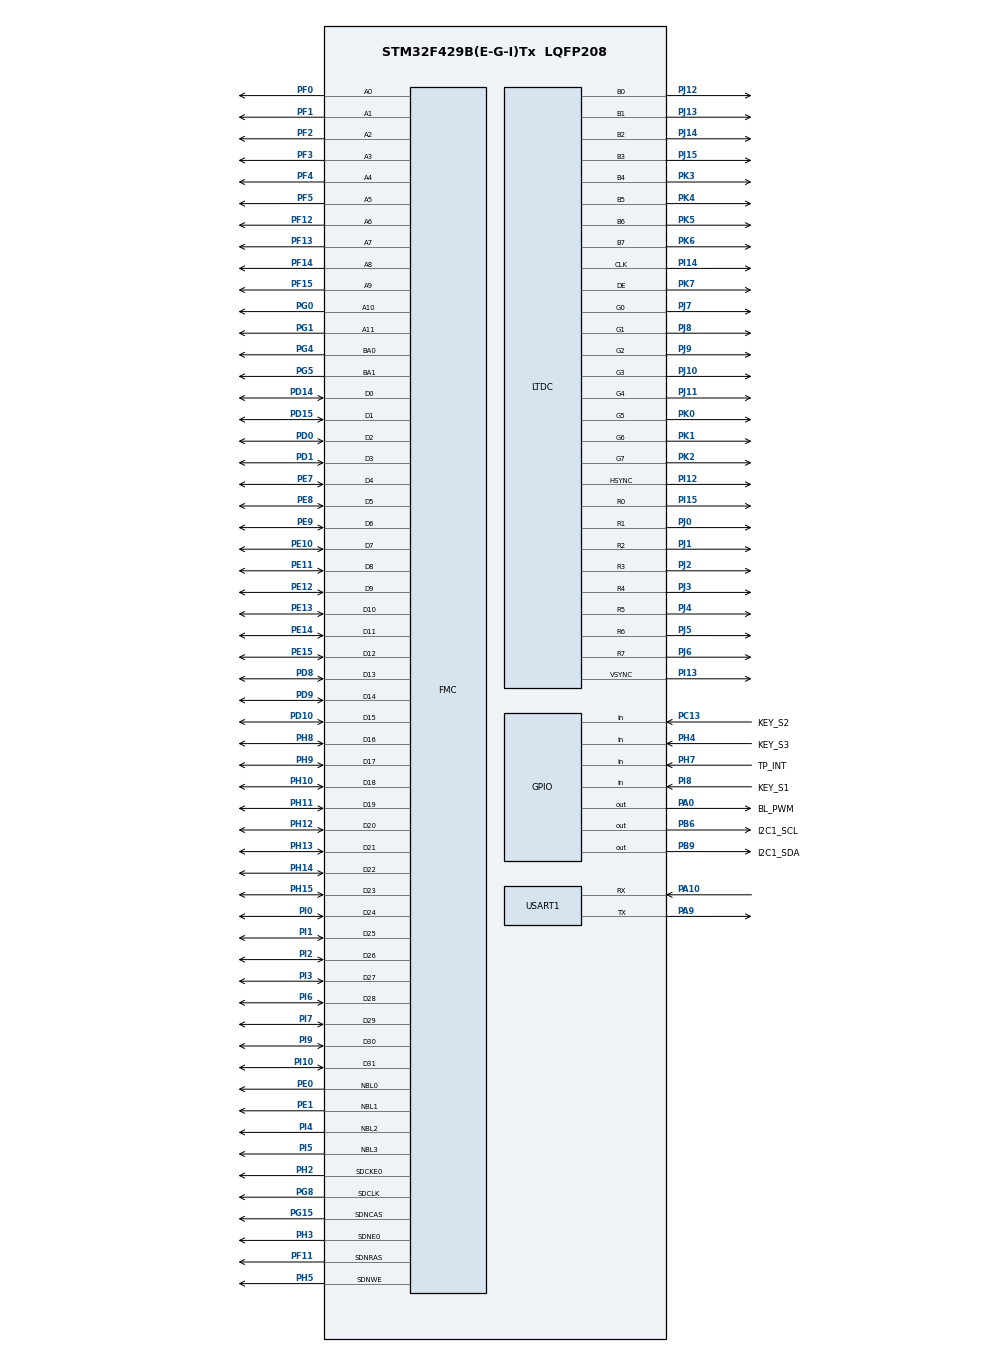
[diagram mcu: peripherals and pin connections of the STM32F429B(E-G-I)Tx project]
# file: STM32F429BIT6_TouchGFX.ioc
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STMicroelectronics.X-CUBE-TOUCHGFX.4.14.0.tgfx_address1=0
SH.FMC_D7_DA7.0=FMC_D7,sd-32b-d1
STMicroelectronics.X-CUBE-TOUCHGFX.4.14.0.tgfx_address2=0
VP_TIM5_VS_ClockSourceINT.Mode=Internal
FREERTOS.Queues01=GUI_MsgQ,16,uint8_t,0,Dynamic,NULL,NULL
PK5.Signal=LTDC_B6
VP_SYS_VS_tim6.Mode=TIM6
SH.FMC_D24.0=FMC_D24,sd-32b-d1
PJ9.Mode=RGB888
FMC.SDClockPeriod2=FMC_SDRAM_CLOCK_PERIOD_2
PH12.Signal=FMC_D20
FMC.RCDDelay1=2
FMC.SDClockPeriod1=FMC_SDRAM_CLOCK_PERIOD_2
SH.FMC_A0.0=FMC_A0,12b-sda1
NVIC.TIM6_DAC_IRQn=true\:0\:0\:false\:false\:true\:false\:false\:true
PK0.Mode=RGB888
PG4.Signal=FMC_A14_BA0
PG8.Signal=FMC_SDCLK
PA14.GPIO_Label=SWC
PG0.Signal=FMC_A10
PJ10.GPIO_Speed=GPIO_SPEED_FREQ_VERY_HIGH
FMC.LoadToActiveDelay1=2
PB9.GPIO_ModeDefaultOutputPP=GPIO_MODE_OUTPUT_OD
PB6.GPIO_Label=I2C1_SCL
PJ8.GPIO_Speed=GPIO_SPEED_FREQ_VERY_HIGH
PK1.Signal=LTDC_G6
SH.FMC_D5_DA5.0=FMC_D5,sd-32b-d1
RCC.SYSCLKSource=RCC_SYSCLKSOURCE_PLLCLK
PJ10.Signal=LTDC_G3
SH.FMC_A15_BA1.0=FMC_BA1,FourSdramBanks1
SH.FMC_D9_DA9.0=FMC_D9,sd-32b-d1
SH.FMC_D25.0=FMC_D25,sd-32b-d1
FREERTOS.configENABLE_FPU=1
FREERTOS.INCLUDE_pcTaskGetTaskName=1
PH5.Signal=FMC_SDNWE
NVIC.DMA2D_IRQn=true\:5\:0\:true\:false\:true\:false\:true\:true
SH.FMC_SDNWE.0=FMC_SDNWE,12b-sda1
PH9.Signal=FMC_D17
SH.FMC_D11_DA11.0=FMC_D11,sd-32b-d1
PJ5.Mode=RGB888
RCC.APB2TimFreq_Value=180000000
PB6.Signal=GPIO_Output
PH1/OSC_OUT.Signal=RCC_OSC_OUT
PD0.Signal=FMC_D2_DA2
PD8.Signal=FMC_D13_DA13
PE1.Signal=FMC_NBL1
PJ14.Mode=RGB888
FMC.SelfRefreshTime1=4
LTDC.PixelFormat_L0=LTDC_PIXEL_FORMAT_RGB565
PK7.Mode=RGB888
SH.FMC_D26.0=FMC_D26,sd-32b-d1
PJ2.Mode=RGB888
PE9.Signal=FMC_D6_DA6
SH.FMC_A2.0=FMC_A2,12b-sda1
PI6.Signal=FMC_D28
PI3.Signal=FMC_D27
PJ1.GPIO_Speed=GPIO_SPEED_FREQ_VERY_HIGH
SH.FMC_D1_DA1.0=FMC_D1,sd-32b-d1
PF3.Signal=FMC_A3
PE10.Signal=FMC_D7_DA7
LTDC.HSync=96
PJ14.Signal=LTDC_B2
Mcu.Package=LQFP208
PB9.Signal=GPIO_Output
NVIC.TimeBase=TIM6_DAC_IRQn
PK6.GPIO_Speed=GPIO_SPEED_FREQ_VERY_HIGH
STMicroelectronics.X-CUBE-TOUCHGFX.4.14.0.tgfx_vsync=vsync_ltdc
PB6.GPIO_ModeDefaultOutputPP=GPIO_MODE_OUTPUT_OD
PJ4.Signal=LTDC_R5
NVIC.TimeBaseIP=TIM6
PA10.Signal=USART1_RX
SH.FMC_D27.0=FMC_D27,sd-32b-d1
PB9.GPIO_PuPd=GPIO_PULLUP
TIM7.AutoReloadPreload=TIM_AUTORELOAD_PRELOAD_ENABLE
FMC.WriteRecoveryTime1=3
SH.FMC_A1.0=FMC_A1,12b-sda1
PI12.GPIO_Speed=GPIO_SPEED_FREQ_VERY_HIGH
PH2.Signal=FMC_SDCKE0
RCC.APB2CLKDivider=RCC_HCLK_DIV2
PJ3.GPIO_Speed=GPIO_SPEED_FREQ_VERY_HIGH
SH.FMC_SDCLK.0=FMC_SDCLK,12b-sda1
LTDC.VSync=2
PF14.Signal=FMC_A8
RCC.APB1TimFreq_Value=90000000
FREERTOS.configGENERATE_RUN_TIME_STATS=1
VP_DMA2D_VS_DMA2D.Mode=DMA2D_Activate
FMC.RowCycleDelay2=7
FMC.RowCycleDelay1=7
PJ13.Mode=RGB888
PJ1.Mode=RGB888
PD15.Signal=FMC_D1_DA1
SH.FMC_D3_DA3.0=FMC_D3,sd-32b-d1
PJ5.GPIO_Speed=GPIO_SPEED_FREQ_VERY_HIGH
PI14.GPIO_Speed=GPIO_SPEED_FREQ_VERY_HIGH
STMicroelectronics.X-CUBE-TOUCHGFX.4.14.0.tgfx_display_interface=disp_ltdc
SH.FMC_A4.0=FMC_A4,12b-sda1
PK4.Signal=LTDC_B5
PH15.Signal=FMC_D23
PA0/WKUP.PinState=GPIO_PIN_SET
FREERTOS.Tasks01=GUI_Task,24,4096,vTaskGUI,As weak,NULL,Dynamic,NULL,NULL;LED_Task,8,256,vTaskLED,As weak,NULL,Dynamic,NULL,NULL;KEY_Task,16,512,vTaskKEY,As weak,NULL,Dynamic,NULL,NULL
PH13.Signal=FMC_D21
SH.FMC_D28.0=FMC_D28,sd-32b-d1
PG5.Signal=FMC_A15_BA1
PC13.Signal=GPIO_Input
SH.FMC_D10_DA10.0=FMC_D10,sd-32b-d1
PB6.GPIO_PuPd=GPIO_PULLUP
FREERTOS.configCHECK_FOR_STACK_OVERFLOW=2
PI12.Signal=LTDC_HSYNC
PD1.Signal=FMC_D3_DA3
SH.FMC_D16.0=FMC_D16,sd-32b-d1
RCC.APB1CLKDivider=RCC_HCLK_DIV4
PJ11.Signal=LTDC_G4
LTDC.ImageWidth_L0=800
PD10.Signal=FMC_D15_DA15
PJ6.Mode=RGB888
SH.FMC_A3.0=FMC_A3,12b-sda1
PJ7.Signal=LTDC_G0
PJ3.Signal=LTDC_R4
PI8.GPIO_Label=KEY_S1
SH.FMC_D29.0=FMC_D29,sd-32b-d1
FMC.CASLatency1=FMC_SDRAM_CAS_LATENCY_3
SH.FMC_D15_DA15.0=FMC_D15,sd-32b-d1
PA9.Signal=USART1_TX
PJ13.GPIO_Speed=GPIO_SPEED_FREQ_VERY_HIGH
SH.FMC_D17.0=FMC_D17,sd-32b-d1
FREERTOS.configUSE_POSIX_ERRNO=0
PJ15.Signal=LTDC_B3
PJ14.GPIO_Speed=GPIO_SPEED_FREQ_VERY_HIGH
PI7.Signal=FMC_D29
FMC.ReadBurst1=FMC_SDRAM_RBURST_ENABLE
SH.FMC_A6.0=FMC_A6,12b-sda1
FMC.ReadBurst2=FMC_SDRAM_RBURST_ENABLE
PE14.Signal=FMC_D11_DA11
PE15.Signal=FMC_D12_DA12
PE8.Signal=FMC_D5_DA5
PI1.Signal=FMC_D25
PI2.Signal=FMC_D26
PA0/WKUP.GPIO_Label=BL_PWM
FREERTOS.INCLUDE_xEventGroupSetBitFromISR=1
PF13.Signal=FMC_A7
PA13.Mode=Serial_Wire
SH.FMC_SDNCAS.0=FMC_SDNCAS,12b-sda1
SH.FMC_NBL2.0=FMC_NBL2,Sd4ByteEnable1
STMicroelectronics.X-CUBE-TOUCHGFX.4.14.0.tgfx_hardware_accelerator=dma_2d
SH.FMC_D18.0=FMC_D18,sd-32b-d1
PJ15.Mode=RGB888
PK1.GPIO_Speed=GPIO_SPEED_FREQ_VERY_HIGH
PK4.Mode=RGB888
USART1.VirtualMode=VM_ASYNC
PB6.PinState=GPIO_PIN_SET
PB9.PinState=GPIO_PIN_SET
SH.FMC_A5.0=FMC_A5,12b-sda1
LTDC.Alpha_L0=255
PJ6.GPIO_Speed=GPIO_SPEED_FREQ_VERY_HIGH
PJ8.Signal=LTDC_G1
ProjectManager.HeapSize=0x400
PJ10.Mode=RGB888
FREERTOS.Mutexes01=xMutex_printf,Dynamic,NULL
NVIC.PriorityGroup=NVIC_PRIORITYGROUP_4
PJ4.Mode=RGB888
PC15/OSC32_OUT.Signal=RCC_OSC32_OUT
PF4.Signal=FMC_A4
SH.FMC_NBL3.0=FMC_NBL3,Sd4ByteEnable1
PB6.GPIO_Speed=GPIO_SPEED_FREQ_HIGH
PI13.GPIO_Speed=GPIO_SPEED_FREQ_VERY_HIGH
SH.FMC_D19.0=FMC_D19,sd-32b-d1
PK5.GPIO_Speed=GPIO_SPEED_FREQ_VERY_HIGH
PI12.Mode=RGB888
Mcu.Family=STM32F4
STMicroelectronics.X-CUBE-TOUCHGFX.4.14.0.ApplicationCcGraphicsJjApplication=TouchGFXOoGenerator
PK7.Signal=LTDC_DE
PK3.Signal=LTDC_B4
SH.FMC_A8.0=FMC_A8,12b-sda1
RCC.CortexFreq_Value=180000000
PK2.GPIO_Speed=GPIO_SPEED_FREQ_VERY_HIGH
PH14.Signal=FMC_D22
PH10.Signal=FMC_D18
SH.FMC_D14_DA14.0=FMC_D14,sd-32b-d1
LTDC.HBP=10
SH.FMC_NBL0.0=FMC_NBL0,Sd4ByteEnable1
SH.FMC_D6_DA6.0=FMC_D6,sd-32b-d1
PA0/WKUP.Signal=GPIO_Output
PC14/OSC32_IN.Mode=LSE-External-Oscillator
SH.FMC_A14_BA0.0=FMC_BA0,FourSdramBanks1
SH.FMC_A11.0=FMC_A11,12b-sda1
PJ2.GPIO_Speed=GPIO_SPEED_FREQ_VERY_HIGH
PC13.GPIO_Label=KEY_S2
PJ9.GPIO_Speed=GPIO_SPEED_FREQ_VERY_HIGH
VP_STMicroelectronics.X-CUBE-TOUCHGFX_VS_GraphicsJjApplication_4.14.0.Mode=GraphicsJjApplication
PG15.Signal=FMC_SDNCAS
ProjectManager.StackSize=0x400
VP_FREERTOS_VS_CMSIS_V2.Mode=CMSIS_V2
PH3.Mode=SdramChipSelect1_1
STMicroelectronics.X-CUBE-TOUCHGFX.4.14.0.tgfx_buffering_strategy=Double
VP_TIM7_VS_ClockSourceINT.Mode=Enable_Timer
PJ6.Signal=LTDC_R7
PJ11.GPIO_Speed=GPIO_SPEED_FREQ_VERY_HIGH
SH.FMC_A7.0=FMC_A7,12b-sda1
PJ2.Signal=LTDC_R3
Mcu.UserConstants=SDRAM_BANK_ADDR,0xC0000000UL
FREERTOS.configUSE_STATS_FORMATTING_FUNCTIONS=1
PH0/OSC_IN.Mode=HSE-External-Oscillator
RCC.HCLKFreq_Value=180000000
SH.FMC_NBL1.0=FMC_NBL1,Sd4ByteEnable1
LTDC.WindowX1_L0=800
PF12.Signal=FMC_A6
FREERTOS.configUSE_MALLOC_FAILED_HOOK=1
TIM7.Period=99
PK2.Mode=RGB888
PI13.Signal=LTDC_VSYNC
SH.FMC_A10.0=FMC_A10,12b-sda1
RCC.AHBFreq_Value=180000000
RCC.HSE_VALUE=8000000
SH.FMC_D8_DA8.0=FMC_D8,sd-32b-d1
FMC.ExitSelfRefreshDelay1=7
FMC.RPDelay2=2
FMC.RPDelay1=2
FREERTOS.configENABLE_BACKWARD_COMPATIBILITY=1
PI8.Signal=GPIO_Input
PI14.Mode=RGB888
SH.FMC_D2_DA2.0=FMC_D2,sd-32b-d1
LTDC.VBP=10
PE13.Signal=FMC_D10_DA10
PH7.GPIO_Label=TP_INT
PA14.Mode=Serial_Wire
PI5.Signal=FMC_NBL3
PK6.Mode=RGB888
PI0.Signal=FMC_D24
PF11.Signal=FMC_SDNRAS
PA0/WKUP.GPIO_Speed=GPIO_SPEED_FREQ_HIGH
PJ7.GPIO_Speed=GPIO_SPEED_FREQ_VERY_HIGH
LTDC.HFP=10
FMC.ReadPipeDelay1=FMC_SDRAM_RPIPE_DELAY_2
FMC.ReadPipeDelay2=FMC_SDRAM_RPIPE_DELAY_2
SH.FMC_SDNRAS.0=FMC_SDNRAS,12b-sda1
DMA2D.ColorMode=DMA2D_OUTPUT_RGB565
LTDC.ActiveW=800
PH1/OSC_OUT.Mode=HSE-External-Oscillator
FREERTOS.configTOTAL_HEAP_SIZE=30720
PJ0.Mode=RGB888
PJ12.Mode=RGB888
SH.FMC_D0_DA0.0=FMC_D0,sd-32b-d1
PJ9.Signal=LTDC_G2
DMA2D.OutputOffset=0
PJ12.Signal=LTDC_B0
PC14/OSC32_IN.Signal=RCC_OSC32_IN
SH.FMC_A9.0=FMC_A9,12b-sda1
PJ1.Signal=LTDC_R2
SH.FMC_D4_DA4.0=FMC_D4,sd-32b-d1
RCC.PLLSAIN=140
PF5.Signal=FMC_A5
PH7.Signal=GPIO_Input
PB9.GPIO_Speed=GPIO_SPEED_FREQ_HIGH
SH.FMC_D30.0=FMC_D30,sd-32b-d1
PJ7.Mode=RGB888
PF0.Signal=FMC_A0
PK4.GPIO_Speed=GPIO_SPEED_FREQ_VERY_HIGH
PE7.Signal=FMC_D4_DA4
PH2.Mode=SdramChipSelect1_1
PI15.Mode=RGB888
NVIC.TIM7_IRQn=true\:0\:0\:false\:false\:true\:true\:true\:true
PK1.Mode=RGB888
RCC.PLLSourceVirtual=RCC_PLLSOURCE_HSE
PK6.Signal=LTDC_B7
NVIC.LTDC_IRQn=true\:5\:0\:true\:false\:true\:false\:true\:true
SH.FMC_D20.0=FMC_D20,sd-32b-d1
PK2.Signal=LTDC_G7
LTDC.FBStartAdress_L0=SDRAM_BANK_ADDR
LTDC.VFP=10
STMicroelectronics.X-CUBE-TOUCHGFX.4.14.0.tgfx_location=By Address
LTDC.WindowY1_L0=480
PB9.GPIO_Label=I2C1_SDA
PJ8.Mode=RGB888
PA10.Mode=Asynchronous
PH11.Signal=FMC_D19
PG1.Signal=FMC_A11
PI14.Signal=LTDC_CLK
SH.FMC_D31.0=FMC_D31,sd-32b-d1
PI10.Signal=FMC_D31
PD9.Signal=FMC_D14_DA14
FREERTOS.configUSE_APPLICATION_TASK_TAG=1
PJ11.Mode=RGB888
PA13.Signal=SYS_JTMS-SWDIO
SH.FMC_D21.0=FMC_D21,sd-32b-d1
PA9.Mode=Asynchronous
PK0.GPIO_Speed=GPIO_SPEED_FREQ_VERY_HIGH
PH4.Signal=GPIO_Input
PJ0.GPIO_Speed=GPIO_SPEED_FREQ_VERY_HIGH
ProjectManager.TargetToolchain=STM32CubeIDE
SH.FMC_D13_DA13.0=FMC_D13,sd-32b-d1
PH8.Signal=FMC_D16
PF2.Signal=FMC_A2
PE11.Signal=FMC_D8_DA8
PK0.Signal=LTDC_G5
PK5.Mode=RGB888
TIM7.Prescaler=179
board=custom
PJ15.GPIO_Speed=GPIO_SPEED_FREQ_VERY_HIGH
RCC.VCOOutputFreq_Value=360000000
PI9.Signal=FMC_D30
PH4.GPIO_Label=KEY_S3
PJ3.Mode=RGB888
PH0/OSC_IN.Signal=RCC_OSC_IN
SH.FMC_D22.0=FMC_D22,sd-32b-d1
RCC.APB2Freq_Value=90000000
LTDC.Layers=0
PK7.GPIO_Speed=GPIO_SPEED_FREQ_VERY_HIGH
PI4.Signal=FMC_NBL2
PJ12.GPIO_Speed=GPIO_SPEED_FREQ_VERY_HIGH
SH.FMC_D12_DA12.0=FMC_D12,sd-32b-d1
PF15.Signal=FMC_A9
PF1.Signal=FMC_A1
PI13.Mode=RGB888
PJ0.Signal=LTDC_R1
Mcu.Name=STM32F429B(E-G-I)Tx
PE0.Signal=FMC_NBL0
PE12.Signal=FMC_D9_DA9
PA13.GPIO_Label=SWD
PD14.Signal=FMC_D0_DA0
RCC.48MHZClocksFreq_Value=90000000
RCC.SYSCLKFreq_VALUE=180000000
PI15.GPIO_Speed=GPIO_SPEED_FREQ_VERY_HIGH
TIM5.Prescaler=19
PC15/OSC32_OUT.Mode=LSE-External-Oscillator
PJ5.Signal=LTDC_R6
SH.FMC_D23.0=FMC_D23,sd-32b-d1
PA14.Signal=SYS_JTCK-SWCLK
RCC.HSI_VALUE=16000000
PH3.Signal=FMC_SDNE0
PK3.Mode=RGB888
RCC.PLLM=4
PK3.GPIO_Speed=GPIO_SPEED_FREQ_VERY_HIGH
RCC.PLLN=180
PI15.Signal=LTDC_R0
TIM5.Period=8399
PJ4.GPIO_Speed=GPIO_SPEED_FREQ_VERY_HIGH
RCC.APB1Freq_Value=45000000
VP_CRC_VS_CRC.Mode=CRC_Activate
LTDC.ImageHeight_L0=480
DMA2D.Mode=DMA2D_M2M
PJ13.Signal=LTDC_B1

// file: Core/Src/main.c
/* USER CODE BEGIN Header */
/**
 ******************************************************************************
 * @file           : main.c
 * @brief          : Main program body
 ******************************************************************************
 * @attention
 *
 * <h2><center>&copy; Copyright (c) 2020 STMicroelectronics.
 * All rights reserved.</center></h2>
 *
 * This software component is licensed by ST under Ultimate Liberty license
 * SLA0044, the "License"; You may not use this file except in compliance with
 * the License. You may obtain a copy of the License at:
 *                             www.st.com/SLA0044
 *
 ******************************************************************************
 */
/* USER CODE END Header */
#include "main.h"
#include "cmsis_os.h"
#include "crc.h"
#include "dma2d.h"
#include "ltdc.h"
#include "tim.h"
#include "usart.h"
#include "gpio.h"
#include "fmc.h"
#include "app_touchgfx.h"

void SystemClock_Config(void);
void MX_FREERTOS_Init(void);

/* USER CODE BEGIN 0 */
/* FMC SDRAM Bank address */
#define SDRAM_TIMEOUT ((uint32_t)0xFFFF)
#define REFRESH_COUNT (1385)

/* FMC SDRAM Mode definition register defines */
#define SDRAM_MODEREG_BURST_LENGTH_1             ((uint16_t)0x0000)
#define SDRAM_MODEREG_BURST_LENGTH_2             ((uint16_t)0x0001)
#define SDRAM_MODEREG_BURST_LENGTH_4             ((uint16_t)0x0002)
#define SDRAM_MODEREG_BURST_LENGTH_8             ((uint16_t)0x0004)
#define SDRAM_MODEREG_BURST_TYPE_SEQUENTIAL      ((uint16_t)0x0000)
#define SDRAM_MODEREG_BURST_TYPE_INTERLEAVED     ((uint16_t)0x0008)
#define SDRAM_MODEREG_CAS_LATENCY_1              ((uint16_t)0x0010)
#define SDRAM_MODEREG_CAS_LATENCY_2              ((uint16_t)0x0020)
#define SDRAM_MODEREG_CAS_LATENCY_3              ((uint16_t)0x0030)
#define SDRAM_MODEREG_OPERATING_MODE_STANDARD    ((uint16_t)0x0000)
#define SDRAM_MODEREG_WRITEBURST_MODE_PROGRAMMED ((uint16_t)0x0000)
#define SDRAM_MODEREG_WRITEBURST_MODE_SINGLE     ((uint16_t)0x0200)

/**
 * @brief  Programs the SDRAM device.
 * @retval None
 */
void MX_SDRAM_InitEx(void) {
    FMC_SDRAM_CommandTypeDef Command;
    __IO uint32_t tmpmrd = 0;

    /* Step 1: Configure a clock configuration enable command */
    Command.CommandMode = FMC_SDRAM_CMD_CLK_ENABLE;
    Command.CommandTarget = FMC_SDRAM_CMD_TARGET_BANK1;
    Command.AutoRefreshNumber = 1;
    Command.ModeRegisterDefinition = 0;

    /* Send the command */
    HAL_SDRAM_SendCommand(&hsdram1, &Command, SDRAM_TIMEOUT);

    /* Step 2: Insert 100 us minimum delay */
    /* Inserted delay is equal to 1 ms due to systick time base unit (ms) */
    HAL_Delay(1);

    /* Step 3: Configure a PALL (precharge all) command */
    Command.CommandMode = FMC_SDRAM_CMD_PALL;
    Command.CommandTarget = FMC_SDRAM_CMD_TARGET_BANK1;
    Command.AutoRefreshNumber = 1;
    Command.ModeRegisterDefinition = 0;

    /* Send the command */
    HAL_SDRAM_SendCommand(&hsdram1, &Command, SDRAM_TIMEOUT);

    /* Step 4: Configure an Auto Refresh command */
    Command.CommandMode = FMC_SDRAM_CMD_AUTOREFRESH_MODE;
    Command.CommandTarget = FMC_SDRAM_CMD_TARGET_BANK1;
    Command.AutoRefreshNumber = 8;
    Command.ModeRegisterDefinition = 0;

    /* Send the command */
    HAL_SDRAM_SendCommand(&hsdram1, &Command, SDRAM_TIMEOUT);

    /* Step 5: Program the external memory mode register */
    tmpmrd = (uint32_t) SDRAM_MODEREG_BURST_LENGTH_1 |\
                        SDRAM_MODEREG_BURST_TYPE_SEQUENTIAL |\
                        SDRAM_MODEREG_CAS_LATENCY_3 |\
                        SDRAM_MODEREG_OPERATING_MODE_STANDARD |\
                        SDRAM_MODEREG_WRITEBURST_MODE_SINGLE;

    Command.CommandMode = FMC_SDRAM_CMD_LOAD_MODE;
    Command.CommandTarget = FMC_SDRAM_CMD_TARGET_BANK1;
    Command.AutoRefreshNumber = 1;
    Command.ModeRegisterDefinition = tmpmrd;

    /* Send the command */
    HAL_SDRAM_SendCommand(&hsdram1, &Command, SDRAM_TIMEOUT);

    /* Step 6: Set the refresh rate counter */
    /* Set the device refresh rate */
    HAL_SDRAM_ProgramRefreshRate(&hsdram1, REFRESH_COUNT);
}
/* USER CODE END 0 */

int main(void)
{

  /* MCU Configuration--------------------------------------------------------*/

  /* Reset of all peripherals, Initializes the Flash interface and the Systick. */
  HAL_Init();

  /* Configure the system clock */
  SystemClock_Config();

  /* Initialize all configured peripherals */
  MX_GPIO_Init();
  MX_DMA2D_Init();
  MX_FMC_Init();
  MX_LTDC_Init();
  MX_TIM5_Init();
  MX_USART1_UART_Init();
  MX_CRC_Init();
  MX_TIM7_Init();
  MX_TouchGFX_Init();
  /* USER CODE BEGIN 2 */
  MX_SDRAM_InitEx();
  /* USER CODE END 2 */

  /* Init scheduler */
  osKernelInitialize();  /* Call init function for freertos objects (in freertos.c) */
  MX_FREERTOS_Init();
  /* Start scheduler */
  osKernelStart();

  /* We should never get here as control is now taken by the scheduler */
  /* Infinite loop */
    while (1) {

    }
}

void SystemClock_Config(void)
{
  LL_FLASH_SetLatency(LL_FLASH_LATENCY_5);
  while(LL_FLASH_GetLatency()!= LL_FLASH_LATENCY_5)
  {
  }
  LL_PWR_SetRegulVoltageScaling(LL_PWR_REGU_VOLTAGE_SCALE1);
  LL_PWR_EnableOverDriveMode();
  LL_RCC_HSE_Enable();

   /* Wait till HSE is ready */
  while(LL_RCC_HSE_IsReady() != 1)
  {

  }
  LL_RCC_PLL_ConfigDomain_SYS(LL_RCC_PLLSOURCE_HSE, LL_RCC_PLLM_DIV_4, 180, LL_RCC_PLLP_DIV_2);
  LL_RCC_PLLSAI_ConfigDomain_LTDC(LL_RCC_PLLSOURCE_HSE, LL_RCC_PLLSAIM_DIV_4, 140, LL_RCC_PLLSAIR_DIV_2, LL_RCC_PLLSAIDIVR_DIV_2);
  LL_RCC_PLL_Enable();

   /* Wait till PLL is ready */
  while(LL_RCC_PLL_IsReady() != 1)
  {

  }
  LL_RCC_PLLSAI_Enable();

   /* Wait till PLL is ready */
  while(LL_RCC_PLLSAI_IsReady() != 1)
  {

  }
  LL_RCC_SetAHBPrescaler(LL_RCC_SYSCLK_DIV_1);
  LL_RCC_SetAPB1Prescaler(LL_RCC_APB1_DIV_4);
  LL_RCC_SetAPB2Prescaler(LL_RCC_APB2_DIV_2);
  LL_RCC_SetSysClkSource(LL_RCC_SYS_CLKSOURCE_PLL);

   /* Wait till System clock is ready */
  while(LL_RCC_GetSysClkSource() != LL_RCC_SYS_CLKSOURCE_STATUS_PLL)
  {

  }
  LL_SetSystemCoreClock(180000000);

   /* Update the time base */
  if (HAL_InitTick (TICK_INT_PRIORITY) != HAL_OK)
  {
    Error_Handler();
  }
  LL_RCC_SetTIMPrescaler(LL_RCC_TIM_PRESCALER_TWICE);
}

void HAL_TIM_PeriodElapsedCallback(TIM_HandleTypeDef *htim)
{
  if (htim->Instance == TIM6) {
    HAL_IncTick();
  }
}

void Error_Handler(void)
{
}

/************************ (C) COPYRIGHT STMicroelectronics *****END OF FILE****/

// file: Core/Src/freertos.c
/* USER CODE BEGIN Header */
/**
  ******************************************************************************
  * File Name          : freertos.c
  * Description        : Code for freertos applications
  ******************************************************************************
  * @attention
  *
  * <h2><center>&copy; Copyright (c) 2020 STMicroelectronics.
  * All rights reserved.</center></h2>
  *
  * This software component is licensed by ST under Ultimate Liberty license
  * SLA0044, the "License"; You may not use this file except in compliance with
  * the License. You may obtain a copy of the License at:
  *                             www.st.com/SLA0044
  *
  ******************************************************************************
  */
/* USER CODE END Header */

#include "FreeRTOS.h"
#include "task.h"
#include "main.h"
#include "cmsis_os.h"

/* Definitions for GUI_Task */
osThreadId_t GUI_TaskHandle;
const osThreadAttr_t GUI_Task_attributes = {
  .name = "GUI_Task",
  .priority = (osPriority_t) osPriorityNormal,
  .stack_size = 4096 * 4
};
/* Definitions for LED_Task */
osThreadId_t LED_TaskHandle;
const osThreadAttr_t LED_Task_attributes = {
  .name = "LED_Task",
  .priority = (osPriority_t) osPriorityLow,
  .stack_size = 256 * 4
};
/* Definitions for KEY_Task */
osThreadId_t KEY_TaskHandle;
const osThreadAttr_t KEY_Task_attributes = {
  .name = "KEY_Task",
  .priority = (osPriority_t) osPriorityBelowNormal,
  .stack_size = 512 * 4
};
/* Definitions for GUI_MsgQ */
osMessageQueueId_t GUI_MsgQHandle;
const osMessageQueueAttr_t GUI_MsgQ_attributes = {
  .name = "GUI_MsgQ"
};
/* Definitions for xMutex_printf */
osMutexId_t xMutex_printfHandle;
const osMutexAttr_t xMutex_printf_attributes = {
  .name = "xMutex_printf"
};

void vTaskGUI(void *argument);
void vTaskLED(void *argument);
void vTaskKEY(void *argument);

void MX_FREERTOS_Init(void); /* (MISRA C 2004 rule 8.1) */

/* Hook prototypes */
void configureTimerForRunTimeStats(void);
unsigned long getRunTimeCounterValue(void);
void vApplicationStackOverflowHook(xTaskHandle xTask, signed char *pcTaskName);
void vApplicationMallocFailedHook(void);

/* USER CODE BEGIN 1 */
/* Functions needed when configGENERATE_RUN_TIME_STATS is on */
__weak void configureTimerForRunTimeStats(void)
{

}

__weak unsigned long getRunTimeCounterValue(void)
{
return 0;
}
/* USER CODE END 1 */

/* USER CODE BEGIN 4 */
__weak void vApplicationStackOverflowHook(xTaskHandle xTask, signed char *pcTaskName)
{
   /* Run time stack overflow checking is performed if
   configCHECK_FOR_STACK_OVERFLOW is defined to 1 or 2. This hook function is
   called if a stack overflow is detected. */
}
/* USER CODE END 4 */

/* USER CODE BEGIN 5 */
__weak void vApplicationMallocFailedHook(void)
{
   /* vApplicationMallocFailedHook() will only be called if
   configUSE_MALLOC_FAILED_HOOK is set to 1 in FreeRTOSConfig.h. It is a hook
   function that will get called if a call to pvPortMalloc() fails.
   pvPortMalloc() is called internally by the kernel whenever a task, queue,
   timer or semaphore is created. It is also called by various parts of the
   demo application. If heap_1.c or heap_2.c are used, then the size of the
   heap available to pvPortMalloc() is defined by configTOTAL_HEAP_SIZE in
   FreeRTOSConfig.h, and the xPortGetFreeHeapSize() API function can be used
   to query the size of free heap space that remains (although it does not
   provide information on how the remaining heap might be fragmented). */
}
/* USER CODE END 5 */

void MX_FREERTOS_Init(void) {
  /* Create the mutex(es) */
  /* creation of xMutex_printf */
  xMutex_printfHandle = osMutexNew(&xMutex_printf_attributes);

  /* Create the queue(s) */
  /* creation of GUI_MsgQ */
  GUI_MsgQHandle = osMessageQueueNew (16, sizeof(uint8_t), &GUI_MsgQ_attributes);

  /* Create the thread(s) */
  /* creation of GUI_Task */
  GUI_TaskHandle = osThreadNew(vTaskGUI, NULL, &GUI_Task_attributes);

  /* creation of LED_Task */
  LED_TaskHandle = osThreadNew(vTaskLED, NULL, &LED_Task_attributes);

  /* creation of KEY_Task */
  KEY_TaskHandle = osThreadNew(vTaskKEY, NULL, &KEY_Task_attributes);

}

__weak void vTaskGUI(void *argument)
{
  for(;;)
  {
      osDelay(1);
  }
}

__weak void vTaskLED(void *argument)
{
  for(;;)
  {
    osDelay(1);
  }
}

__weak void vTaskKEY(void *argument)
{
  for(;;)
  {
    osDelay(1);
  }
}

/************************ (C) COPYRIGHT STMicroelectronics *****END OF FILE****/
